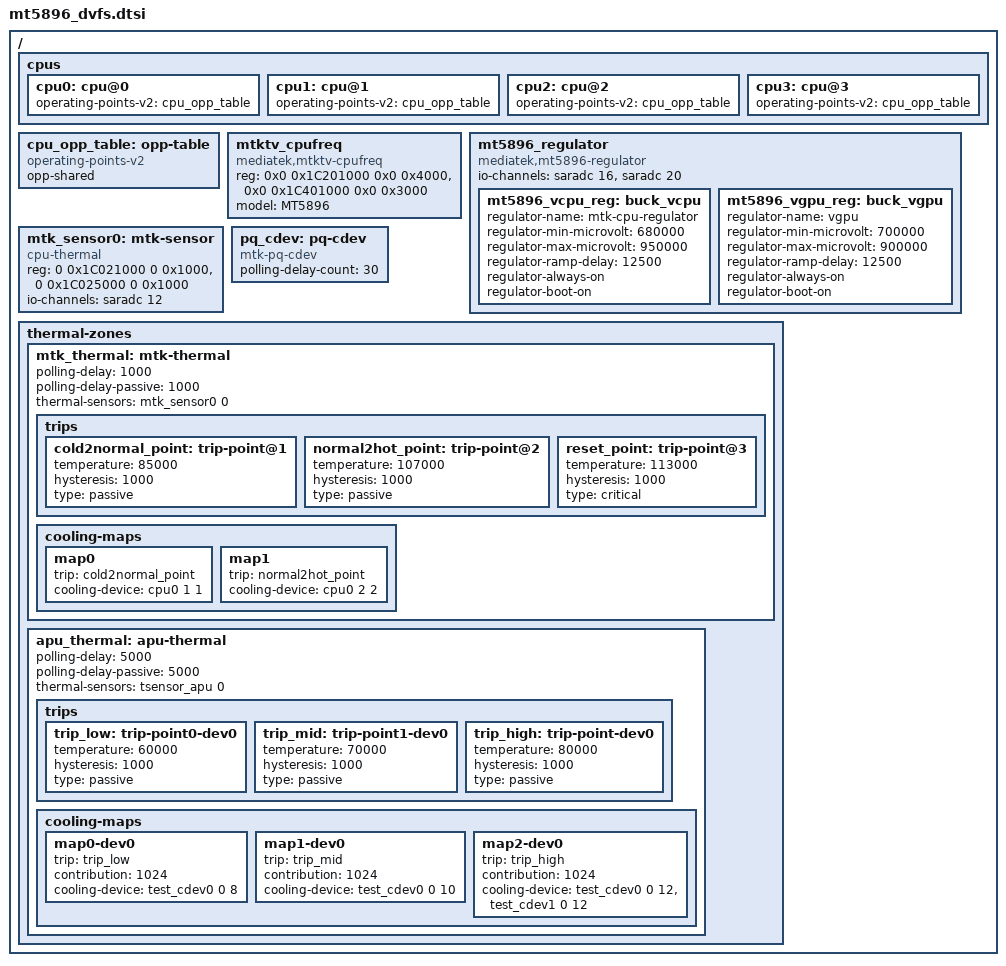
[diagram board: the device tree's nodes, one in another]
// SPDX-License-Identifier: (GPL-2.0 OR BSD-3-Clause)
/*
 * Copyright (c) 2021 MediaTek Inc.
 */

/ {
	cpus {
		#address-cells = <0x02>;
		#size-cells = <0x00>;

		cpu0: cpu@0 {
			operating-points-v2 = <&cpu_opp_table>;
			#cooling-cells = <0x2>;
		};

		cpu1: cpu@1 {
			operating-points-v2 = <&cpu_opp_table>;
			#cooling-cells = <0x2>;
		};

		cpu2: cpu@2 {
			operating-points-v2 = <&cpu_opp_table>;
			#cooling-cells = <0x2>;
		};

		cpu3: cpu@3 {
			operating-points-v2 = <&cpu_opp_table>;
			#cooling-cells = <0x2>;
		};
	};

	cpu_opp_table: opp-table {
		compatible = "operating-points-v2";
		opp-shared;
		/* move to dtbo
		boost-0 = <1800000000>;
		boost-1 = <1800000000>;
		boost-2 = <1800000000>;

		opp-900000000 {
			opp-hz = /bits/ 64 <900000000>;
			opp-microvolt = <750000>;
			opp-corner-offset = <0>;
		};
		opp-1600000000 {
			opp-hz = /bits/ 64 <1600000000>;
			opp-microvolt = <750000>;
			opp-corner-offset = <0>;
		};
		opp-1800000000 {
			opp-hz = /bits/ 64 <1800000000>;
			opp-microvolt = <800000>;
			opp-corner-offset = <0>;
		};
		*/
	};

	mtktv_cpufreq: mtktv_cpufreq {
		compatible = "mediatek,mtktv-cpufreq";
		reg = <0x0 0x1C201000 0x0 0x4000>,
		      <0x0 0x1C401000 0x0 0x3000>;
		model = "MT5896";
		status = "ok";
	};

	mt5896_regulator: mt5896_regulator {
		compatible = "mediatek,mt5896-regulator";
		io-channels = <&saradc 16>,<&saradc 20>;
		io-channel-names = "adc16","adc20";
		mt5896_vcpu_reg: buck_vcpu {
			regulator-name = "mtk-cpu-regulator";
			regulator-min-microvolt = < 680000>;
			regulator-max-microvolt = < 950000>;
			regulator-ramp-delay = <12500>;
			regulator-always-on;
			regulator-boot-on;
		};
		mt5896_vgpu_reg: buck_vgpu {
			regulator-name = "vgpu";
			regulator-min-microvolt = < 700000>;
			regulator-max-microvolt = < 900000>;
			regulator-ramp-delay = <12500>;
			regulator-always-on;
			regulator-boot-on;
		};
	};

	mtk_sensor0: mtk-sensor {
		compatible = "cpu-thermal";
		#thermal-sensor-cells = <1>;
		reg = <0 0x1C021000 0 0x1000>,
		      <0 0x1C025000 0 0x1000>;
		io-channels = <&saradc 12>;
		io-channel-names = "adc12";
	};

	pq_cdev: pq-cdev {
		compatible = "mtk-pq-cdev";
		#cooling-cells = <2>; /* min followed by max */
		polling-delay-count = <30>;
	};

	thermal-zones {
		mtk_thermal: mtk-thermal {
			polling-delay = <1000>;
			polling-delay-passive = <1000>;

			thermal-sensors = <&mtk_sensor0 0>;
			trips {
				cold2normal_point: trip-point@1 {
					temperature = <85000>; /* millicelsius */
					hysteresis = <1000>; /* millicelsius */
					type = "passive";
				};
				normal2hot_point: trip-point@2 {
					temperature = <107000>; /* millicelsius */
					hysteresis = <1000>; /* millicelsius */
					type = "passive";
				};
				reset_point: trip-point@3 {
					temperature = <113000>; /* millicelsius */
					hysteresis = <1000>; /* millicelsius */
					type = "critical";
				};
			};
			cooling-maps {
				map0 {
					trip = <&cold2normal_point>;
					cooling-device = <&cpu0 1 1>;
				};
				map1 {
					trip = <&normal2hot_point>;
					cooling-device = <&cpu0 2 2>;
				};
			};
		};

		apu_thermal: apu-thermal {
			polling-delay = <5000>;
			polling-delay-passive = <5000>;

			thermal-sensors = <&tsensor_apu 0>;
			trips {
				trip_low: trip-point0-dev0 {
					temperature = <60000>; /* millicelsius */
					hysteresis = <1000>; /* millicelsius */
					type = "passive";
				};

				trip_mid: trip-point1-dev0 {
					temperature = <70000>; /* millicelsius */
					hysteresis = <1000>; /* millicelsius */
					type = "passive";
				};

				trip_high: trip-point-dev0 {
					temperature = <80000>; /* millicelsius */
					hysteresis = <1000>; /* millicelsius */
					type = "passive";
				};
			};

			cooling-maps {
				map0-dev0 {
					trip = <&trip_low>;
					contribution = <1024>;
					cooling-device = <&test_cdev0 0 8>;
				};

				map1-dev0 {
					trip = <&trip_mid>;
					contribution = <1024>;
					cooling-device = <&test_cdev0 0 10>;
				};

				map2-dev0 {
					trip = <&trip_high>;
					contribution = <1024>;
					cooling-device = <&test_cdev0 0 12>, <&test_cdev1 0 12>;
				};
			};
		};
	};
};
